# MAX32550 register map
Vendor: Maxim Integrated; File version: 1.0
Registers are 32-bit, read-write, reset 0x0 unless marked. A register's access mark holds for its fields unless they carry their own. Offsets are from the block's base; [hi:lo] are bit positions; 'fields as' and 'values as' point back to an identical list.

## InstructionCacheController — Registers to control the instruction cache
Base 0x4002A000
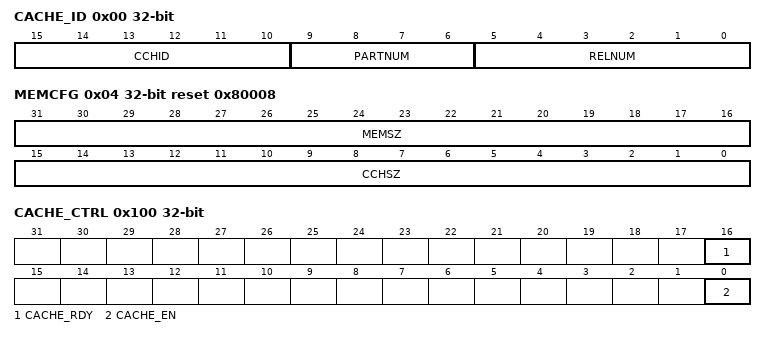
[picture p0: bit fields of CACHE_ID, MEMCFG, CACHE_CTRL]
0x00 CACHE_ID ro
  [15:10] CCHID — Cache ID. This field reflects the value of the C_ID_CACHEID configuration parameter.
  [9:6] PARTNUM — Part Number. This field reflects the value of C_ID_PART_NUMBER configuration parameter.
  [5:0] RELNUM — Release Number. Identifies the RTL release version.
0x04 MEMCFG ro reset 0x80008 — Memory Configuration Register
  [31:16] MEMSZ — Main Memory Size. Indicates the total size, in units of 128 Kbytes, of code memory accessible to the cache controller.
  [15:0] CCHSZ — Cache Size. Indicates total size in Kbytes of cache.
0x100 CACHE_CTRL — Cache Control and Status Register
  [16] CACHE_RDY — Cache Ready flag. Cleared by hardware when at any time the cache as a whole is invalidated (including a system reset). When this bit is 0, the cache is effectively in bypass mode (instruction fetches will come from main memory or from the line fill buffer). Set by hardware when the invalidate operation is complete and the cache is ready.
    0=notReady; 1=ready
  [0] CACHE_EN — Cache Enable. Controls whether the cache is bypassed or is in use. Changing the state of this bit will cause the instruction cache to be flushed and its contents invalidated.
    0=disable (Cache Bypassed. Instruction data is stored in the line fill buffer but is not written to main cache memory array.); 1=enable (Cache Enabled)
0x700 INVALIDATE — Invalidate All Registers

## DAC — Digital to Analog Converter
Base 0x40038000; register names take the prefix DAC_
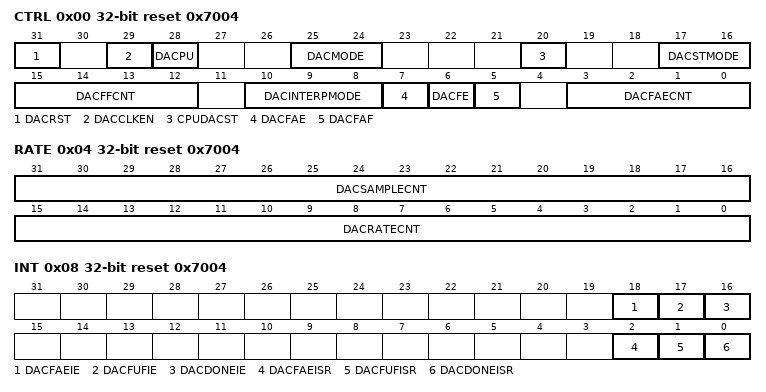
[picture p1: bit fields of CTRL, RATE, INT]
0x00 CTRL reset 0x7004 — DAC Control Register
  [31] DACRST wo — DAC Timing Generator Reset. Setting this bit to a 1 resets the FIFO and all state machines.
    1=reset (Starts reset operation)
  [29] DACCLKEN — DAC Interface Clk Gate Enable. Writing this bit to a 1 will enable clock to use DAC.
    0=disable; 1=enable
  [28] DACPU — DAC Power Up. Writing this bit to a 1 will power up the DAC.
    0=disable; 1=enable
  [25:24] DACMODE — DAC Operation Mode
    0=onAvail (Output Data in FIFO as soon as available.); 1=perDacRateCnt (Output DacSmplCnt[15:0] Data points from FIFO at Ts defined by DacRateCnt[15:0].); 2=perDacReg (Use DAC_REG control.); 3=toModeChange (Output DacSmplCnt[15:0] Data points from FIFO at Ts until mode changed.)
  [20] CPUDACST wo — DAC Start Strobe. The CPU may write this bit to a 1 to start a conversion when DACSTMODE = 10.
  [17:16] DACSTMODE — DAC Output Start Mode
    0=notEmpty (Start on FIFO not empty); 2=strobe (Start on local DAC Start Strobe)
  [15:12] DACFFCNT — DAC FIFO Almost Full Level. This value serves as a threshold: if the write data pointer in the FIFO exceeds this count, then the DACFAF flag is set.
  [10:8] DACINTERPMODE — DAC Interpolation Mode
    0=disabled; 1=interp1to2 (1:2 Interpolation); 2=interp1to4 (1:4 Interpolation); 3=interp1to8 (1:8 Interpolation)
  [7] DACFAE ro — FIFO Almost Empty
  [6] DACFE ro — FIFO Empty
  [5] DACFAF ro — FIFO Almost Full
  [3:0] DACFAECNT — DAC FIFO Almost Empty Level. This value serves as a threshold- if the write data pointer in the FIFO exceeds this count, then the DACFAE flag is set.
0x04 RATE reset 0x7004 — DAC Output Rate and Sample Control
  [31:16] DACSAMPLECNT — Number of data points to output in DACMODE=01. If DACINTERPMODE = 0, DACSMPLCNT = Number samples to output. Else, DACSMPLCNT = (Number uninterpolated samples -1) * 2^DACINTERPMODE + 1.
  [15:0] DACRATECNT — Delay between output samples in DACMODE=01. Ts = (DACRATECNT + 2)*(1/24MHz) based on a 12MHz crystal.
0x08 INT reset 0x7004 — DAC Interrupt Register
  [18] DACFAEIE — FIFO almost empty interrupt enable. Setting this bit to a 1 allows the FIFO almost empty condition to trigger an interrupt.
    0=disable; 1=enable
  [17] DACFUFIE — FIFO underflow interrupt enable. Setting this bit to a 1 allows the FIFO underflow condition to trigger an interrupt.
    0=disable; 1=enable
  [16] DACDONEIE — DAC Output Done Interrupt enable. Setting this bit to a 1 allows the DAC output condition to trigger an interrupt.
    0=disable; 1=enable
  [2] DACFAEISR write-1-clears — FIFO almost empty interrupt status. This bit is set to a 1 by hardware when an interrupt is triggered by the DAC FIFO Almost Empty condition.
    on read: 0=inactive (No interrupt is pending); 1=pending (An interrupt is pending) | on write: 1=clear
  [1] DACFUFISR write-1-clears — FIFO underflow interrupt status. This bit is set to a 1 by hardware when an interrupt is triggered by the DAC FIFO Underflow condition.
    values as DACFAEISR
  [0] DACDONEISR write-1-clears — DAC output Done Interrupt status. This bit is set to a 1 by hardware when an interrupt is triggered by the DAC output Done condition.
    values as DACFAEISR
0x0C REG reset 0x7004 — DAC Input Register
